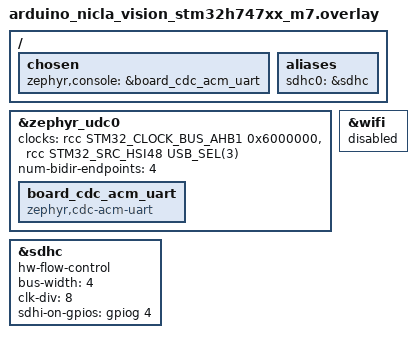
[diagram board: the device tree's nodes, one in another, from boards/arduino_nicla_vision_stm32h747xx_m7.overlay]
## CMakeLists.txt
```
# SPDX-License-Identifier: Apache-2.0

cmake_minimum_required(VERSION 3.28.0)
find_package(Zephyr REQUIRED HINTS $ENV{ZEPHYR_BASE})
project(sdmmc_subsys_test)

file(GLOB app_sources src/*.c)
target_sources(app PRIVATE ${app_sources})
```

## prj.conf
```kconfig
CONFIG_TEST=y
CONFIG_ZTEST=y
CONFIG_SDHC=y
CONFIG_SDIO_STACK=y
CONFIG_LOG=y
```

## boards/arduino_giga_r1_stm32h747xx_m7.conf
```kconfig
# Copyright (c) 2025 EXALT Technologies.
# SPDX-License-Identifier: Apache-2.0

CONFIG_HEAP_MEM_POOL_SIZE=24576
```

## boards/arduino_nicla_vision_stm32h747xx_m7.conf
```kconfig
CONFIG_LOG=y
CONFIG_LOG_DEFAULT_LEVEL=3
CONFIG_LOG_MODE_MINIMAL=y
CONFIG_SDHC=y
CONFIG_SDMMC_STM32=y
CONFIG_HEAP_MEM_POOL_SIZE=24576
CONFIG_LOG_MODE_DEFERRED=y
CONFIG_CACHE_MANAGEMENT=y
```

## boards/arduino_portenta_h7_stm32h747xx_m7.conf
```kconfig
# Copyright (c) 2022 Benjamin Björnsson <benjamin.bjornsson@gmail.com>.
# SPDX-License-Identifier: Apache-2.0
CONFIG_LOG=y
CONFIG_LOG_DEFAULT_LEVEL=3
CONFIG_LOG_MODE_MINIMAL=y
CONFIG_SDHC=y
CONFIG_SDMMC_STM32=y
CONFIG_HEAP_MEM_POOL_SIZE=24576
CONFIG_CACHE_MANAGEMENT=y
```

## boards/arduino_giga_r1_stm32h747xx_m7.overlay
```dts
/*
 * Copyright (c) 2025 EXALT Technologies.
 *
 * SPDX-License-Identifier: Apache-2.0
 */

&wifi {
	status = "disabled";
};
```

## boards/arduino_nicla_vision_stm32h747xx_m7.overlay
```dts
/*
 * Copyright (c) 2025 EXALT Technologies.
 *
 * SPDX-License-Identifier: Apache-2.0
 */

/ {
	chosen {
		zephyr,console = &board_cdc_acm_uart;
	};

	aliases {
		sdhc0 = &sdhc;
	};
};

&zephyr_udc0 {
	clocks = <&rcc STM32_CLOCK_BUS_AHB1 0x6000000>,
		 <&rcc STM32_SRC_HSI48 USB_SEL(3)>;
	num-bidir-endpoints = < 4 >;

	board_cdc_acm_uart: board_cdc_acm_uart {
		status = "okay";
		compatible = "zephyr,cdc-acm-uart";
	};
};

&wifi {
	status = "disabled";
};

&sdhc {
	hw-flow-control;
	bus-width = <4>;
	clk-div = <8>;
	sdhi-on-gpios = <&gpiog 4 GPIO_ACTIVE_HIGH>;
};
```

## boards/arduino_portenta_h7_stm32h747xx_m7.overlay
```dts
/*
 * Copyright (c) 2025 EXALT Technologies.
 *
 * SPDX-License-Identifier: Apache-2.0
 */

&boot_partition {
	reg = <0x00000000 0x00020000>;
};

&scratch_partition {
	reg = <0x00020000 0x00020000>;
};

&slot0_partition {
	reg = <0x00040000 0x001c0000>;
};

&slot1_partition {
	reg = <0x00200000 0x001c0000>;
};

&wifi {
	status = "disabled";
};
```

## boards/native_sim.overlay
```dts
/*
 * Copyright 2026 Alif Semiconductor
 *
 * SPDX-License-Identifier: Apache-2.0
 *
 */

/ {
	aliases {
		sdhc0 = &sdhc0;
	};

	sdhc0: sdhc {
		compatible = "zephyr,sdhc-emul";
		card-type = "sdio";
		capacity-blocks = <1024>;
		bus-width = <4>;
		max-bus-freq = <25000000>;
		voltage-330;
		card-inserted;
		sdio-func-count = <1>;
		status = "okay";
	};
};
```

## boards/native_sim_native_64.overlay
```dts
/*
 * Copyright 2026 Alif Semiconductor
 *
 * SPDX-License-Identifier: Apache-2.0
 *
 */

#include "native_sim.overlay"
```

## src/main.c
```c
/*
 * Copyright 2022 NXP
 *
 * SPDX-License-Identifier: Apache-2.0
 */

#include <zephyr/sd/sdio.h>
#include <zephyr/device.h>
#include <zephyr/drivers/disk.h>
#include <zephyr/ztest.h>


static const struct device *sdhc_dev = DEVICE_DT_GET(DT_ALIAS(sdhc0));
static struct sd_card card;

/*
 * Verify that SD stack can initialize an SDIO card.
 * This test must run first, to ensure the card is initialized.
 */
ZTEST(sd_stack, test_0_init)
{
	int ret;

	zassert_true(device_is_ready(sdhc_dev), "SDHC device is not ready");

	ret = sd_is_card_present(sdhc_dev);
	zassert_equal(ret, 1, "SD card not present in slot");

	ret = sd_init(sdhc_dev, &card);
	zassert_equal(ret, 0, "Card initialization failed");
}

/*
 * Verify that a register read works. Given the custom nature of SDIO devices,
 * we just read from the card common I/O area.
 */
ZTEST(sd_stack, test_read)
{
	int ret;
	uint8_t reg = 0xFF;

	/* Read from card common I/O area. */
	ret = sdio_read_byte(&card.func0, SDIO_CCCR_CCCR, &reg);
	zassert_equal(ret, 0, "SD card read failed");
	/* Check to make sure CCCR read actually returned valid data */
	zassert_not_equal(reg, 0xFF, "CCCR read returned invalid data");
}

/*
 * Verify that a register write works. Given the custom nature of SDIO devices,
 * we just write to the card common I/O area.
 */
ZTEST(sd_stack, test_write)
{
	int ret;
	uint8_t data = 0x01;
	uint8_t reg = 0xFF;
	uint8_t new_reg_value = 0xFF;

	/* Read from card common I/O area. */
	ret = sdio_read_byte(&card.func0, SDIO_CCCR_BUS_IF, &reg);
	zassert_equal(ret, 0, "SD card read failed");

	/* Write to card common I/O area. */
	ret = sdio_write_byte(&card.func0, SDIO_CCCR_BUS_IF, data);
	zassert_equal(ret, 0, "SD card write failed");

	/* Read after write to verify that data was written */
	ret = sdio_read_byte(&card.func0, SDIO_CCCR_BUS_IF, &new_reg_value);
	zassert_equal(ret, 0, "SD card read failed");
	new_reg_value = new_reg_value & SDIO_CCCR_BUS_IF_WIDTH_MASK;
	zassert_equal(new_reg_value, data, "read data was not as expected");
}

/* Simply dump the card configuration. */
ZTEST(sd_stack, test_card_config)
{
	switch (card.card_voltage) {
	case SD_VOL_1_2_V:
		TC_PRINT("Card voltage: 1.2V\n");
		break;
	case SD_VOL_1_8_V:
		TC_PRINT("Card voltage: 1.8V\n");
		break;
	case SD_VOL_3_0_V:
		TC_PRINT("Card voltage: 3.0V\n");
		break;
	case SD_VOL_3_3_V:
		TC_PRINT("Card voltage: 3.3V\n");
		break;
	default:
		zassert_unreachable("Card voltage is not known value");
	}
	zassert_equal(card.status, CARD_INITIALIZED, "Card status is not OK");
	switch (card.card_speed) {
	case SD_TIMING_SDR12:
		TC_PRINT("Card timing: SDR12\n");
		break;
	case SD_TIMING_SDR25:
		TC_PRINT("Card timing: SDR25\n");
		break;
	case SD_TIMING_SDR50:
		TC_PRINT("Card timing: SDR50\n");
		break;
	case SD_TIMING_SDR104:
		TC_PRINT("Card timing: SDR104\n");
		break;
	case SD_TIMING_DDR50:
		TC_PRINT("Card timing: DDR50\n");
		break;
	default:
		zassert_unreachable("Card timing is not known value");
	}
	switch (card.type) {
	case CARD_SDIO:
		TC_PRINT("Card type: SDIO\n");
		break;
	case CARD_SDMMC:
		TC_PRINT("Card type: SDMMC\n");
		break;
	case CARD_COMBO:
		TC_PRINT("Card type: combo card\n");
		break;
	default:
		zassert_unreachable("Card type is not known value");
	}
	if (card.sd_version >= SD_SPEC_VER3_0) {
		TC_PRINT("Card spec: 3.0\n");
	} else if (card.sd_version >= SD_SPEC_VER2_0) {
		TC_PRINT("Card spec: 2.0\n");
	} else if (card.sd_version >= SD_SPEC_VER1_1) {
		TC_PRINT("Card spec: 1.1\n");
	} else if (card.sd_version >= SD_SPEC_VER1_0) {
		TC_PRINT("Card spec: 1.0\n");
	} else {
		zassert_unreachable("Card spec is unknown value");
	}
}

/* verify the cmd53 */
ZTEST(sd_stack, test_cmd53)
{
	uint8_t wbuf[512];
	uint8_t rbuf[512];

	zassert_ok(sdio_set_block_size(&card.func0, 512));

	for (int i = 0; i < 64; i++) {
		wbuf[i] = (uint8_t)i;
	}
	zassert_ok(sdio_write_fifo(&card.func0, 0, wbuf, 64));
	memset(rbuf, 0, 64);
	zassert_ok(sdio_read_fifo(&card.func0, 0, rbuf, 64));
	zassert_mem_equal(wbuf, rbuf, 64);

	for (int i = 0; i < 512; i++) {
		wbuf[i] = (uint8_t)(i ^ 0xAA);
	}
	zassert_ok(sdio_write_blocks_fifo(&card.func0, 0, wbuf, 1));
	memset(rbuf, 0, 512);
	zassert_ok(sdio_read_blocks_fifo(&card.func0, 0, rbuf, 1));
	zassert_mem_equal(wbuf, rbuf, 512);
}

ZTEST_SUITE(sd_stack, NULL, NULL, NULL, NULL, NULL);
```
